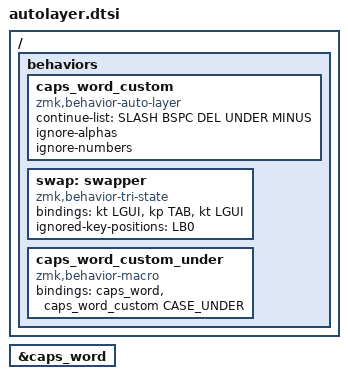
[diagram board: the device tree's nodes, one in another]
#include <behaviors/num_word.dtsi>

&caps_word { // Mods deactivate caps-word, requires PR #1451. [TODO: rebase]
  /delete-property/ ignore-modifiers;
};

/ {
  behaviors {
    caps_word_custom: caps_word_custom {
      compatible = "zmk,behavior-auto-layer";
      #binding-cells = <1>;
      continue-list = <SLASH BSPC DEL UNDER MINUS>;
      ignore-alphas;
      ignore-numbers;
    };

    swap: swapper {
      compatible = "zmk,behavior-tri-state";
      #binding-cells = <0>;
      bindings = <&kt LGUI>, <&kp TAB>, <&kt LGUI>;
      ignored-key-positions = <LB0>;
    };
  };
};

ZMK_MACRO(caps_word_custom_under, bindings = <&caps_word &caps_word_custom CASE_UNDER>;)

#define CAPS_UNDER &caps_word_custom_under
#define WORD_UNDER &caps_word_custom CASE_UNDER
#define WORD_PATH &caps_word_custom CASE_SLASH
#define WORD_SHIFT &caps_word_custom CASE_SHIFT
#define NUM_WORD &num_word NUM

#define SWAP &swap
